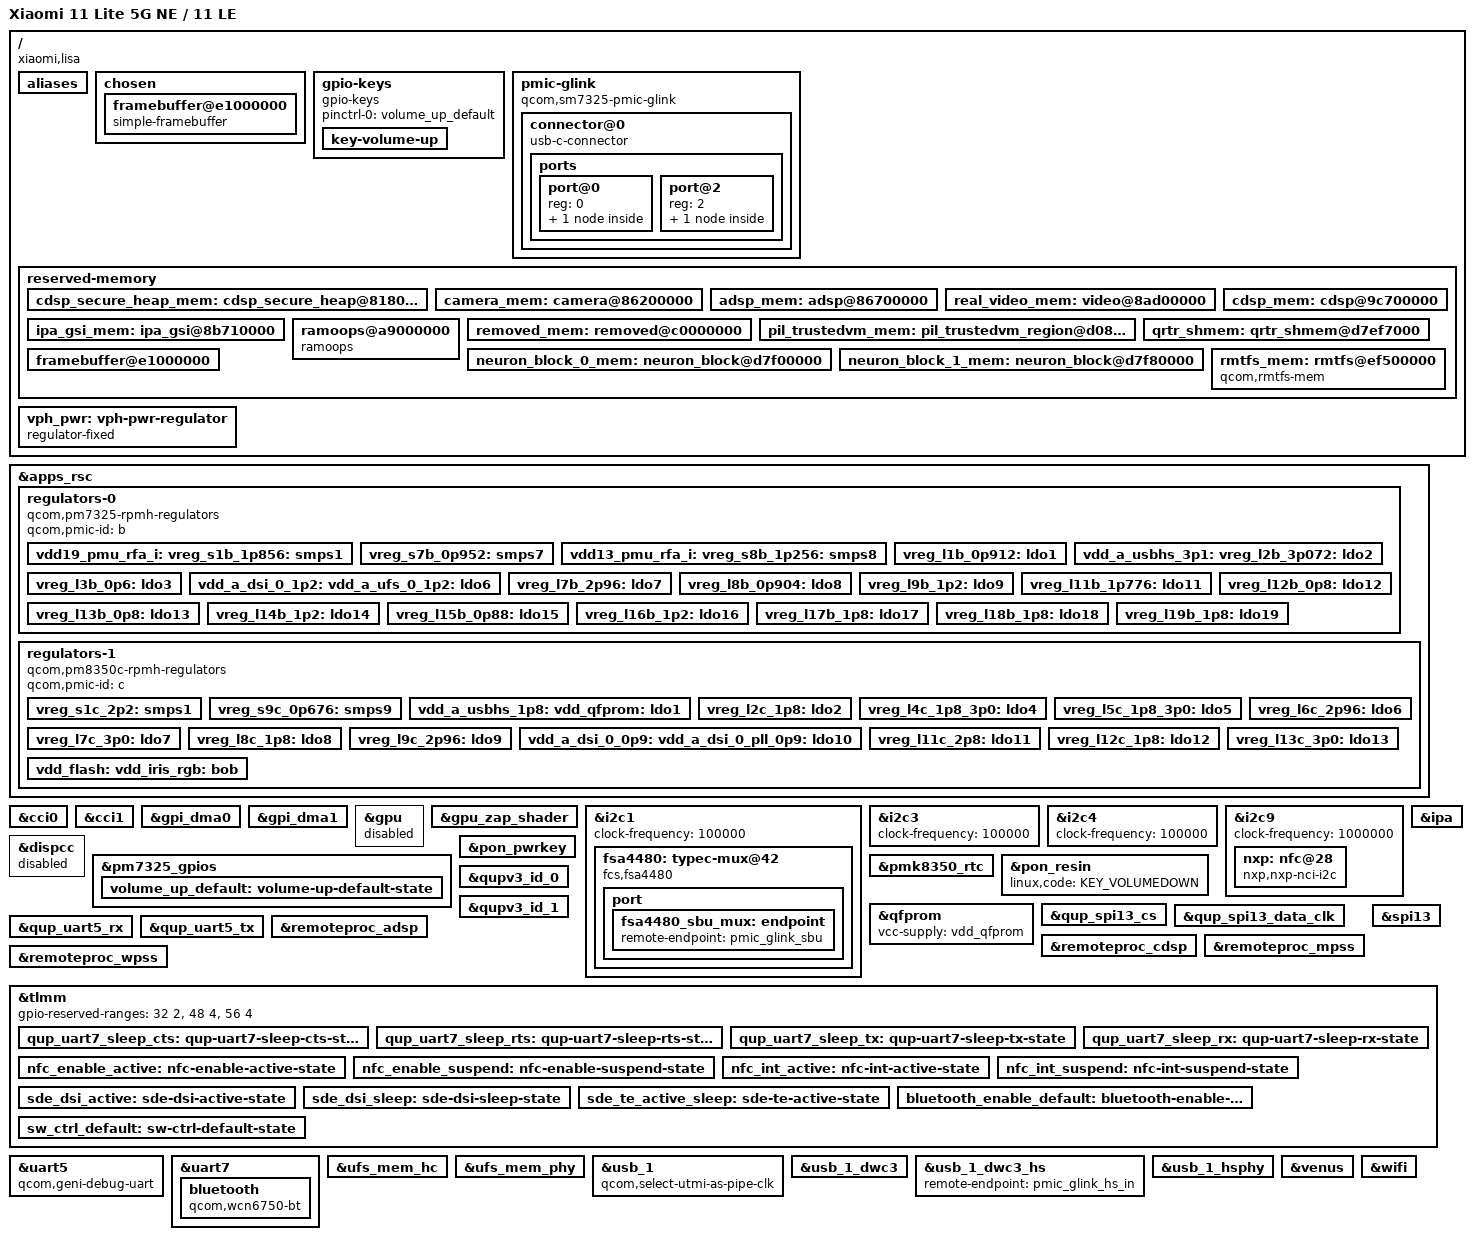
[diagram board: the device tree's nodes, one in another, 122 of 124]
// SPDX-License-Identifier: BSD-3-Clause
/*
 * Copyright (c) 2024, Jens Reidel <adrian@travitia.xyz>
 */

/dts-v1/;

#include <dt-bindings/arm/qcom,ids.h>
#include <dt-bindings/gpio/gpio.h>
#include <dt-bindings/regulator/qcom,rpmh-regulator.h>
#include <dt-bindings/leds/common.h>

#include <dt-bindings/pinctrl/qcom,pmic-gpio.h>
#include "sm7325.dtsi"
#include "pm7325.dtsi"
#include "pm8350b.dtsi" /* PM7325B */
#include "pm8350c.dtsi" /* PM7350C */
#include "pmk8350.dtsi" /* PMK7325 */

/* The following reserved memory regions have different addresses or sizes */
/delete-node/ &adsp_mem;
/delete-node/ &cdsp_mem;
/delete-node/ &rmtfs_mem;

/ {
	model = "Xiaomi 11 Lite 5G NE / 11 LE";
	compatible = "xiaomi,lisa", "qcom,sm7325";
	qcom,msm-id = <QCOM_ID_SM7325 0x10000>;
	qcom,board-id = <0x1000b 0x00>;
	chassis-type = "handset";

	aliases {
		serial0 = &uart5;
		serial1 = &uart7;
	};

	chosen {
		#address-cells = <2>;
		#size-cells = <2>;
		ranges;

		stdout-path = "serial0:115200n8";
		bootargs = "earlycon clk_ignore_unused pd_ignore_unused console=tty0 PMOS_NOSPLASH";

		framebuffer@e1000000 {
			compatible = "simple-framebuffer";
			reg = <0x0 0xe1000000 0x0 (1080 * 2400 * 4)>;
			width = <1080>;
			height = <2400>;
			stride = <(1080 * 4)>;
			format = "a8r8g8b8";
		};
	};

	gpio-keys {
		compatible = "gpio-keys";

		pinctrl-0 = <&volume_up_default>;
		pinctrl-names = "default";

		key-volume-up {
			label = "Volume up";
			gpios = <&pm7325_gpios 6 GPIO_ACTIVE_LOW>;
			linux,code = <KEY_VOLUMEUP>;
		};
	};

	pmic-glink {
		compatible = "qcom,sm7325-pmic-glink",
			     "qcom,pmic-glink";

		#address-cells = <1>;
		#size-cells = <0>;

		connector@0 {
			compatible = "usb-c-connector";
			reg = <0>;
			power-role = "dual";
			data-role = "dual";

			ports {
				#address-cells = <1>;
				#size-cells = <0>;

				port@0 {
					reg = <0>;

					pmic_glink_hs_in: endpoint {
						remote-endpoint = <&usb_1_dwc3_hs>;
					};
				};

				port@2 {
					reg = <2>;

					pmic_glink_sbu: endpoint {
						remote-endpoint = <&fsa4480_sbu_mux>;
					};
				};
			};
		};
	};

	reserved-memory {
		#address-cells = <2>;
		#size-cells = <2>;
		ranges;

		cdsp_secure_heap_mem: cdsp_secure_heap@81800000 {
			reg = <0x0 0x81800000 0x0 0x1e00000>;
			no-map;
		};

		camera_mem: camera@86200000 {
			reg = <0x0 0x86200000 0x0 0x500000>;
			no-map;
		};

		adsp_mem: adsp@86700000 {
			reg = <0x0 0x86700000 0x0 0x4000000>;
			no-map;
		};

		/* Mainline video_mem is downstream cvp_mem */
		real_video_mem: video@8ad00000 {
			reg = <0x0 0x8ad00000 0x0 0x500000>;
			no-map;
		};

		ipa_gsi_mem: ipa_gsi@8b710000 {
			reg = <0x0 0x8b710000 0x0 0xa000>;
			no-map;
		};

		cdsp_mem: cdsp@9c700000 {
			reg = <0x0 0x9c700000 0x0 0x1e00000>;
			no-map;
		};

		ramoops@a9000000 {
			compatible = "ramoops";
			reg = <0x0 0xa9000000 0x0 0x200000>;
			pmsg-size = <0x200000>;
			mem-type = <0x02>;
		};

		removed_mem: removed@c0000000 {
			reg = <0x0 0xc0000000 0x0 0x5100000>;
			no-map;
		};

		pil_trustedvm_mem: pil_trustedvm_region@d0800000 {
			reg = <0x0 0xd0800000 0x0 0x76f7000>;
			no-map;
		};

		qrtr_shmem: qrtr_shmem@d7ef7000 {
			reg = <0x0 0xd7ef7000 0x0 0x9000>;
			no-map;
		};

		neuron_block_0_mem: neuron_block@d7f00000 {
			reg = <0x0 0xd7f00000 0x0 0x80000>;
			no-map;
		};

		neuron_block_1_mem: neuron_block@d7f80000 {
			reg = <0x0 0xd7f80000 0x0 0x80000>;
			no-map;
		};

		framebuffer@e1000000 {
			reg = <0x0 0xe1000000 0x0 (1080 * 2400 * 4)>;
			no-map;
		};

		rmtfs_mem: rmtfs@ef500000 {
			compatible = "qcom,rmtfs-mem";
			reg = <0x0 0xef500000 0x0 0x280000>;
			no-map;

			qcom,client-id = <1>;
			qcom,vmid = <QCOM_SCM_VMID_MSS_MSA>,
				    <QCOM_SCM_VMID_NAV>;
		};
	};

	/*
	thermal-zones {
		camera-thermal {
			polling-delay-passive = <0>;
			polling-delay = <0>;
			thermal-sensors = <&pmk8350_adc_tm 2>;

			trips {
				active-config0 {
					temperature = <125000>;
					hysteresis = <1000>;
					type = "passive";
				};
			};
		};

		chg-skin-thermal {
			polling-delay-passive = <0>;
			polling-delay = <0>;
			thermal-sensors = <&pmk8350_adc_tm 6>;

			trips {
				active-config0 {
					temperature = <125000>;
					hysteresis = <1000>;
					type = "passive";
				};
			};
		};

		conn-thermal {
			polling-delay-passive = <0>;
			polling-delay = <0>;
			thermal-sensors = <&pmk8350_adc_tm 5>;

			trips {
				active-config0 {
					temperature = <125000>;
					hysteresis = <1000>;
					type = "passive";
				};
			};
		};

		quiet-thermal {
			polling-delay-passive = <0>;
			polling-delay = <0>;
			thermal-sensors = <&pmk8350_adc_tm 1>;

			trips {
				active-config0 {
					temperature = <125000>;
					hysteresis = <1000>;
					type = "passive";
				};
			};
		};

		rear-cam-thermal {
			polling-delay-passive = <0>;
			polling-delay = <0>;
			thermal-sensors = <&pmk8350_adc_tm 4>;

			trips {
				active-config0 {
					temperature = <125000>;
					hysteresis = <1000>;
					type = "passive";
				};
			};
		};

		sdm-skin-thermal {
			polling-delay-passive = <0>;
			polling-delay = <0>;
			thermal-sensors = <&pmk8350_adc_tm 3>;

			trips {
				active-config0 {
					temperature = <125000>;
					hysteresis = <1000>;
					type = "passive";
				};
			};
		};

		xo-thermal {
			polling-delay-passive = <0>;
			polling-delay = <0>;
			thermal-sensors = <&pmk8350_adc_tm 0>;

			trips {
				active-config0 {
					temperature = <125000>;
					hysteresis = <1000>;
					type = "passive";
				};
			};
		};
	};
	*/

	vph_pwr: vph-pwr-regulator {
		compatible = "regulator-fixed";
		regulator-name = "vph_pwr";
		regulator-min-microvolt = <3700000>;
		regulator-max-microvolt = <3700000>;
	};

	// S2B is really ebi.lvl but it's there for supply map completeness sake.
	/*
	vreg_s2b_0p7: smpa3-regulator {
		compatible = "regulator-fixed";
		regulator-name = "vreg_s2b_0p7";

		regulator-min-microvolt = <65535>;
		regulator-max-microvolt = <65535>;
		regulator-always-on;
		vin-supply = <&vph_pwr>;
	};
	*/
};

&apps_rsc {
	regulators-0 {
		compatible = "qcom,pm7325-rpmh-regulators";
		qcom,pmic-id = "b";

		/*
		vdd-s1-supply = <&vph_pwr>;
		vdd-s2-supply = <&vph_pwr>;
		vdd-s7-supply = <&vph_pwr>;
		vdd-s8-supply = <&vph_pwr>;

		vdd-l1-l4-l12-l15-supply = <&vreg_s7b_0p952>;
		vdd-l2-l7-supply = <&vreg_bob>;
		vdd-l3-supply = <&vreg_s2b_0p7>;
		vdd-l5-supply = <&vreg_s2b_0p7>;
		vdd-l6-l9-l10-supply = <&vreg_s8b_1p256>;
		vdd-l8-supply = <&vreg_s7b_0p952>;
		vdd-l11-l17-l18-l19-supply = <&vreg_s1b_1p856>;
		vdd-l13-supply = <&vreg_s7b_0p952>;
		vdd-l14-l16-supply = <&vreg_s8b_1p256>;
		*/

		/*
		 * S2, L4-L5 are ARCs:
		 * S2 - ebi.lvl,
		 * L4 - lmx.lvl,
		 * l5 - lcx.lvl.
		 *
		 * L10 are unused.
		 */

		vdd19_pmu_rfa_i:
		vreg_s1b_1p856: smps1 {
			regulator-min-microvolt = <1840000>;
			regulator-max-microvolt = <2040000>;
		};

		vreg_s7b_0p952: smps7 {
			regulator-min-microvolt = <535000>;
			regulator-max-microvolt = <1120000>;
		};

		vdd13_pmu_rfa_i:
		vreg_s8b_1p256: smps8 {
			regulator-min-microvolt = <1200000>;
			regulator-max-microvolt = <1500000>;
			regulator-initial-mode = <RPMH_REGULATOR_MODE_RET>;
		};

		vreg_l1b_0p912: ldo1 {
			regulator-min-microvolt = <825000>;
			regulator-max-microvolt = <925000>;
			regulator-initial-mode = <RPMH_REGULATOR_MODE_HPM>;
		};

		vdd_a_usbhs_3p1:
		vreg_l2b_3p072: ldo2 {
			regulator-min-microvolt = <2700000>;
			regulator-max-microvolt = <3544000>;
			regulator-initial-mode = <RPMH_REGULATOR_MODE_HPM>;
		};

		vreg_l3b_0p6: ldo3 {
			regulator-min-microvolt = <312000>;
			regulator-max-microvolt = <910000>;
			regulator-initial-mode = <RPMH_REGULATOR_MODE_HPM>;
		};

		vdd_a_dsi_0_1p2:
		vdd_a_ufs_0_1p2:
		vreg_l6b_1p2: ldo6 {
			regulator-min-microvolt = <1140000>;
			regulator-max-microvolt = <1260000>;
			regulator-initial-mode = <RPMH_REGULATOR_MODE_HPM>;
			regulator-allow-set-load;
			regulator-allowed-modes = <RPMH_REGULATOR_MODE_LPM
						   RPMH_REGULATOR_MODE_HPM>;
		};

		vreg_l7b_2p96: ldo7 {
			regulator-min-microvolt = <2400000>;
			regulator-max-microvolt = <3544000>;
			regulator-initial-mode = <RPMH_REGULATOR_MODE_HPM>;
			regulator-allow-set-load;
			regulator-allowed-modes = <RPMH_REGULATOR_MODE_LPM
						   RPMH_REGULATOR_MODE_HPM>;
		};

		vreg_l8b_0p904: ldo8 {
			regulator-min-microvolt = <870000>;
			regulator-max-microvolt = <970000>;
			regulator-initial-mode = <RPMH_REGULATOR_MODE_HPM>;
		};

		vreg_l9b_1p2: ldo9 {
			regulator-min-microvolt = <1200000>;
			regulator-max-microvolt = <1304000>;
			regulator-initial-mode = <RPMH_REGULATOR_MODE_HPM>;
			regulator-allow-set-load;
			regulator-allowed-modes = <RPMH_REGULATOR_MODE_LPM
						   RPMH_REGULATOR_MODE_HPM>;
		};

		vreg_l11b_1p776: ldo11 {
			regulator-min-microvolt = <1504000>;
			regulator-max-microvolt = <2000000>;
			regulator-initial-mode = <RPMH_REGULATOR_MODE_HPM>;
		};

		vreg_l12b_0p8: ldo12 {
			regulator-min-microvolt = <751000>;
			regulator-max-microvolt = <824000>;
			regulator-initial-mode = <RPMH_REGULATOR_MODE_HPM>;
		};

		vreg_l13b_0p8: ldo13 {
			regulator-min-microvolt = <530000>;
			regulator-max-microvolt = <824000>;
			regulator-initial-mode = <RPMH_REGULATOR_MODE_HPM>;
		};

		vreg_l14b_1p2: ldo14 {
			regulator-min-microvolt = <1080000>;
			regulator-max-microvolt = <1304000>;
			regulator-initial-mode = <RPMH_REGULATOR_MODE_HPM>;
		};

		vreg_l15b_0p88: ldo15 {
			regulator-min-microvolt = <765000>;
			regulator-max-microvolt = <1020000>;
			regulator-initial-mode = <RPMH_REGULATOR_MODE_HPM>;
		};

		vreg_l16b_1p2: ldo16 {
			regulator-min-microvolt = <1100000>;
			regulator-max-microvolt = <1300000>;
			regulator-initial-mode = <RPMH_REGULATOR_MODE_HPM>;
		};

		vreg_l17b_1p8: ldo17 {
			regulator-min-microvolt = <1700000>;
			regulator-max-microvolt = <1900000>;
			regulator-initial-mode = <RPMH_REGULATOR_MODE_HPM>;
		};

		vreg_l18b_1p8: ldo18 {
			regulator-min-microvolt = <1800000>;
			regulator-max-microvolt = <2000000>;
			regulator-initial-mode = <RPMH_REGULATOR_MODE_HPM>;
		};

		vreg_l19b_1p8: ldo19 {
			regulator-min-microvolt = <1800000>;
			regulator-max-microvolt = <2000000>;
			regulator-initial-mode = <RPMH_REGULATOR_MODE_HPM>;
		};
	};

	regulators-1 {
		compatible = "qcom,pm8350c-rpmh-regulators";
		qcom,pmic-id = "c";

		/*
		vdd-s1-supply = <&vph_pwr>;
		vdd-s2-supply = <&vph_pwr>;
		vdd-s5-supply = <&vph_pwr>;
		vdd-s7-supply = <&vph_pwr>;
		vdd-s9-supply = <&vph_pwr>;
		vdd-s10-supply = <&vph_pwr>;

		vdd-l1-l12-supply = <&vreg_s1b_1p856>;
		vdd-l2-l8-supply = <&vreg_s1b_1p856>;
		*/
		/*
		 * Doesn't work :/
		 * vdd-l3-l4-l5-l7-l13-supply = <&vreg_bob>;
		 */
		/*
		vdd-l6-l9-l11-supply = <&vreg_bob>;
		vdd-l10-supply = <&vreg_s7b_0p952>;

		vdd-bob-supply = <&vph_pwr>;
		*/

		/*
		 * S2, S5, S7, S10 are ARCs:
		 * S2 - cx.lvl,
		 * S5 - mss.lvl,
		 * S7 - gfx.lvl,
		 * S10 - mx.lvl.
		 */

		vreg_s1c_2p2: smps1 {
			regulator-min-microvolt = <2190000>;
			regulator-max-microvolt = <2210000>;
		};

		vreg_s9c_0p676: smps9 {
			regulator-min-microvolt = <1010000>;
			regulator-max-microvolt = <1170000>;
		};

		vdd_a_usbhs_1p8:
		vdd_qfprom:
		vreg_l1c_1p8: ldo1 {
			regulator-min-microvolt = <1800000>;
			regulator-max-microvolt = <1980000>;
			regulator-initial-mode = <RPMH_REGULATOR_MODE_HPM>;
		};

		vreg_l2c_1p8: ldo2 {
			regulator-min-microvolt = <1620000>;
			regulator-max-microvolt = <1980000>;
			regulator-initial-mode = <RPMH_REGULATOR_MODE_HPM>;
		};

		/*
		vreg_l3c_3p0: ldo3 {
			regulator-min-microvolt = <3300000>;
			regulator-max-microvolt = <3300000>;
			regulator-initial-mode = <RPMH_REGULATOR_MODE_HPM>;
			// regulator-always-on;
		};
		*/

		vreg_l4c_1p8_3p0: ldo4 {
			regulator-min-microvolt = <1620000>;
			regulator-max-microvolt = <3300000>;
			regulator-initial-mode = <RPMH_REGULATOR_MODE_HPM>;
		};

		vreg_l5c_1p8_3p0: ldo5 {
			regulator-min-microvolt = <1620000>;
			regulator-max-microvolt = <3300000>;
			regulator-initial-mode = <RPMH_REGULATOR_MODE_HPM>;
		};

		vreg_l6c_2p96: ldo6 {
			regulator-min-microvolt = <1650000>;
			regulator-max-microvolt = <3544000>;
			regulator-initial-mode = <RPMH_REGULATOR_MODE_HPM>;
		};

		vreg_l7c_3p0: ldo7 {
			regulator-min-microvolt = <3000000>;
			regulator-max-microvolt = <3544000>;
			regulator-initial-mode = <RPMH_REGULATOR_MODE_HPM>;
		};

		vreg_l8c_1p8: ldo8 {
			regulator-min-microvolt = <1620000>;
			regulator-max-microvolt = <2000000>;
			regulator-initial-mode = <RPMH_REGULATOR_MODE_HPM>;
			regulator-always-on;
		};

		vreg_l9c_2p96: ldo9 {
			regulator-min-microvolt = <2700000>;
			regulator-max-microvolt = <3544000>;
			regulator-initial-mode = <RPMH_REGULATOR_MODE_HPM>;
		};

		vdd_a_dsi_0_0p9:
		vdd_a_dsi_0_pll_0p9:
		vdd_a_ufs_0_core:
		vdd_a_usbhs_core:
		vreg_l10c: ldo10 {
			regulator-min-microvolt = <720000>;
			regulator-max-microvolt = <1050000>;
			regulator-initial-mode = <RPMH_REGULATOR_MODE_HPM>;
			regulator-allow-set-load;
			regulator-allowed-modes = <RPMH_REGULATOR_MODE_LPM
						   RPMH_REGULATOR_MODE_HPM>;
		};

		vreg_l11c_2p8: ldo11 {
			regulator-min-microvolt = <2800000>;
			regulator-max-microvolt = <3544000>;
			regulator-initial-mode = <RPMH_REGULATOR_MODE_HPM>;
		};

		vreg_l12c_1p8: ldo12 {
			regulator-min-microvolt = <1650000>;
			regulator-max-microvolt = <2000000>;
			regulator-initial-mode = <RPMH_REGULATOR_MODE_HPM>;
		};

		vreg_l13c_3p0: ldo13 {
			regulator-min-microvolt = <2700000>;
			regulator-max-microvolt = <3544000>;
			regulator-initial-mode = <RPMH_REGULATOR_MODE_HPM>;
		};

		vdd_flash:
		vdd_iris_rgb:
		vdd_mic_bias:
		vreg_bob: bob {
			regulator-min-microvolt = <3008000>;
			regulator-max-microvolt = <3960000>;
			regulator-initial-mode = <RPMH_REGULATOR_MODE_AUTO>;
		};
	};
};

&cci0 {
	status = "okay";
};

&cci1 {
	status = "okay";
};

&gpi_dma0 {
	status = "okay";
};

&gpi_dma1 {
	status = "okay";
};

&gpu {
	status = "okay";
};

&gpu_zap_shader {
	firmware-name = "qcom/sm7325/xiaomi/lisa/a660_zap.mbn";
};

&i2c1 {
	clock-frequency = <100000>;
	status = "okay";

	/* awinic,aw210xx_led @ 20 */

	fsa4480: typec-mux@42 {
		compatible = "fcs,fsa4480";
		reg = <0x42>;

		interrupts-extended = <&tlmm 2 IRQ_TYPE_LEVEL_LOW>;

		vcc-supply = <&vreg_bob>;
		mode-switch;
		orientation-switch;

		port {
			fsa4480_sbu_mux: endpoint {
				remote-endpoint = <&pmic_glink_sbu>;
			};
		};
	};

	/*
	 * I guess this is also not used:
	 *
	 * nq rtc6226 @ 64
	 */
};

&i2c3 {
	clock-frequency = <100000>;
	status = "okay";

	/* tfa,tfa98xx @ 34 */
	/* tfa,tfa98xx @ 35 */
};

&i2c4 {
	clock-frequency = <100000>;
	status = "okay";

	/* awinic,aw8624_haptic @ 5a */
};

&i2c9 {
	clock-frequency = <1000000>;
	status = "okay";

	nxp: nfc@28 {
		compatible = "nxp,nxp-nci-i2c";
		reg = <0x28>;

		interrupt-parent = <&tlmm>;
		interrupts = <41 IRQ_TYPE_NONE>;

		enable-gpios = <&tlmm 38 GPIO_ACTIVE_HIGH>;
		firmware-gpios = <&tlmm 40 GPIO_ACTIVE_HIGH>;

		pinctrl-names = "default", "sleep";
		pinctrl-0 = <&nfc_enable_active>, <&nfc_int_active>;
		pinctrl-1 = <&nfc_enable_suspend>, <&nfc_int_suspend>;
	};
};

&ipa {
	qcom,gsi-loader = "self";
	memory-region = <&ipa_fw_mem>;
	firmware-name = "qcom/sm7325/xiaomi/lisa/ipa_fws.mbn";
	status = "okay";
};

&dispcc {
	status = "disabled";
};

&gpu {
	status = "disabled";
};

/*
&mdss {
	status = "okay";
};

&mdss_dsi {
	vdda-supply = <&vdd_a_dsi_0_1p2>;
	status = "okay";

	drm_panel: panel@0 {
		compatible = "mdss,k9d-36-02-0a-dsc";
		reg = <0>;

		reset-gpios = <&tlmm 44 GPIO_ACTIVE_LOW>;

		vdd-supply = <&vreg_l13c_3p0>;
		vddio-supply = <&vreg_l12c_1p8>;

		pinctrl-0 = <&sde_dsi_active &sde_te_active_sleep>;
		pinctrl-1 = <&sde_dsi_sleep &sde_te_active_sleep>;
		pinctrl-names = "default", "sleep";

		port {
			panel_in: endpoint {
				remote-endpoint = <&mdss_dsi0_out>;
			};
		};
	};
};

&mdss_dsi0_out {
	data-lanes = <0 1 2 3>;
	remote-endpoint = <&panel_in>;
};

&mdss_dsi_phy {
	vdds-supply = <&vdd_a_dsi_0_0p9>;
	status = "okay";
};
*/

&pm7325_gpios {
	volume_up_default: volume-up-default-state {
		pins = "gpio6";
		function = PMIC_GPIO_FUNC_NORMAL;
		power-source = <1>;
		bias-pull-up;
		input-enable;
	};
};

/*
&pm8350c_flash {
	status = "okay";

	led-0 {
		function = LED_FUNCTION_FLASH;
		color = <LED_COLOR_ID_WHITE>;
		led-sources = <1>, <4>;
		led-max-microamp = <500000>;
		flash-max-microamp = <1500000>;
		flash-max-timeout-us = <1280000>;
	};
};
*/

&pmk8350_rtc {
	status = "okay";
};

&pon_pwrkey {
	status = "okay";
};

&pon_resin {
	linux,code = <KEY_VOLUMEDOWN>;
	status = "okay";
};

&qfprom {
	vcc-supply = <&vdd_qfprom>;
};

&qup_spi13_cs {
	drive-strength = <6>;
	bias-disable;
};

&qup_spi13_data_clk {
	drive-strength = <6>;
	bias-disable;
};

&qup_uart5_rx {
	drive-strength = <2>;
	bias-disable;
};

&qup_uart5_tx {
	drive-strength = <2>;
	bias-disable;
};

&qupv3_id_0 {
	status = "okay";
};

&qupv3_id_1 {
	status = "okay";
};

&remoteproc_adsp {
	firmware-name = "qcom/sm7325/xiaomi/lisa/adsp.mbn";
	status = "okay";
};

&remoteproc_cdsp {
	firmware-name = "qcom/sm7325/xiaomi/lisa/cdsp.mbn";
	status = "okay";
};

&remoteproc_mpss {
	firmware-name = "qcom/sm7325/xiaomi/lisa/modem.mbn";
	status = "okay";
};

&remoteproc_wpss {
	firmware-name = "qcom/sm7325/xiaomi/lisa/wpss.mbn";
	status = "okay";
};

&spi13 {
	status = "okay";

	/* xiaomi,k9-spi @ 0 */
};


&tlmm {
	/*
	 * 32-33: SMB1394 (SPMI)
	 * 56-59: fingerprint reader (SPI)
	 */
	gpio-reserved-ranges = <32 2>, <48 4>, <56 4>;

	qup_uart7_sleep_cts: qup-uart7-sleep-cts-state {
		pins = "gpio28";
		function = "gpio";
		/*
		 * Configure a bias-bus-hold on CTS to lower power
		 * usage when Bluetooth is turned off. Bus hold will
		 * maintain a low power state regardless of whether
		 * the Bluetooth module drives the pin in either
		 * direction or leaves the pin fully unpowered.
		 */
		bias-bus-hold;
	};

	qup_uart7_sleep_rts: qup-uart7-sleep-rts-state {
		pins = "gpio29";
		function = "gpio";
		/*
		 * Configure pull-down on RTS. As RTS is active low
		 * signal, pull it low to indicate the BT SoC that it
		 * can wakeup the system anytime from suspend state by
		 * pulling RX low (by sending wakeup bytes).
		 */
		bias-pull-down;
	};

	qup_uart7_sleep_tx: qup-uart7-sleep-tx-state {
		pins = "gpio30";
		function = "gpio";
		/*
		 * Configure pull-up on TX when it isn't actively driven
		 * to prevent BT SoC from receiving garbage during sleep.
		 */
		bias-pull-up;
	};

	qup_uart7_sleep_rx: qup-uart7-sleep-rx-state {
		pins = "gpio31";
		function = "gpio";
		/*
		 * Configure a pull-up on RX. This is needed to avoid
		 * garbage data when the TX pin of the Bluetooth module
		 * is floating which may cause spurious wakeups.
		 */
		bias-pull-up;
	};

	nfc_enable_active: nfc-enable-active-state {
		pins = "gpio38", "gpio40", "gpio39";
		function = "gpio";
		drive-strength = <2>;
		bias-disable;
	};

	nfc_enable_suspend: nfc-enable-suspend-state {
		pins = "gpio38", "gpio40", "gpio39";
		function = "gpio";
		drive-strength = <2>;
		bias-disable;
	};

	nfc_int_active: nfc-int-active-state {
		pins = "gpio41";
		function = "gpio";
		drive-strength = <2>;
		bias-pull-down;
	};

	nfc_int_suspend: nfc-int-suspend-state {
		pins = "gpio41";
		function = "gpio";
		drive-strength = <2>;
		bias-pull-down;
	};

	sde_dsi_active: sde-dsi-active-state {
		pins = "gpio44";
		function = "gpio";
		drive-strength = <8>;
		bias-disable;
	};

	sde_dsi_sleep: sde-dsi-sleep-state {
		pins = "gpio44";
		function = "gpio";
		drive-strength = <2>;
		bias-pull-down;
	};

	sde_te_active_sleep: sde-te-active-state {
		pins = "gpio80";
		function = "mdp_vsync";
		drive-strength = <2>;
		bias-pull-down;
	};

	bluetooth_enable_default: bluetooth-enable-default-state {
		pins = "gpio85";
		function = "gpio";
		output-low;
		bias-disable;
	};

	sw_ctrl_default: sw-ctrl-default-state {
		pins = "gpio86";
		function = "gpio";
		bias-pull-down;
	};
};

&uart5 {
	compatible = "qcom,geni-debug-uart";
	status = "okay";
};

&uart7 {
	/delete-property/interrupts;
	interrupts-extended = <&intc GIC_SPI 608 IRQ_TYPE_LEVEL_HIGH>,
			      <&tlmm 31 IRQ_TYPE_EDGE_FALLING>;

	pinctrl-1 = <&qup_uart7_sleep_cts>,
		    <&qup_uart7_sleep_rts>,
		    <&qup_uart7_sleep_tx>,
		    <&qup_uart7_sleep_rx>;
	pinctrl-names = "default", "sleep";

	status = "okay";

	bluetooth: bluetooth {
		compatible = "qcom,wcn6750-bt";

		pinctrl-0 = <&bluetooth_enable_default>, <&sw_ctrl_default>;
		pinctrl-names = "default";

		enable-gpios = <&tlmm 85 GPIO_ACTIVE_HIGH>;
		swctrl-gpios = <&tlmm 86 GPIO_ACTIVE_HIGH>;

		vddio-supply = <&vreg_l19b_1p8>;
		vddaon-supply = <&vreg_s7b_0p952>;
		vddbtcxmx-supply = <&vreg_s7b_0p952>;
		vddrfacmn-supply = <&vreg_s7b_0p952>;
		vddrfa0p8-supply = <&vreg_s7b_0p952>;
		vddrfa1p2-supply = <&vdd13_pmu_rfa_i>;
		vddrfa1p7-supply = <&vdd19_pmu_rfa_i>;
		vddrfa2p2-supply = <&vreg_s1c_2p2>;
		vddasd-supply = <&vreg_l11c_2p8>;
		max-speed = <3200000>;

		qcom,local-bd-address-broken;
	};
};

&ufs_mem_hc {
	reset-gpios = <&tlmm 175 GPIO_ACTIVE_LOW>;

	vcc-supply = <&vreg_l7b_2p96>;
	vcc-max-microamp = <800000>;
	/*
	 * Technically l9b enables an eLDO (supplied by s1b) which then powers
	 * VCCQ2 of the UFS.
	 */
	vccq-supply = <&vreg_l9b_1p2>;
	vccq-max-microamp = <900000>;

	status = "okay";
};

&ufs_mem_phy {
	vdda-phy-supply = <&vdd_a_ufs_0_core>;
	vdda-pll-supply = <&vdd_a_ufs_0_1p2>;
	status = "okay";
};

&usb_1 {
	/* USB 2.0 only */
	qcom,select-utmi-as-pipe-clk;
	status = "okay";
};

&usb_1_dwc3 {
	dr_mode = "otg";
	usb-role-switch;
	maximum-speed = "high-speed";
	/* Remove USB3 phy */
	phys = <&usb_1_hsphy>;
	phy-names = "usb2-phy";
};

&usb_1_dwc3_hs {
	remote-endpoint = <&pmic_glink_hs_in>;
};

&usb_1_hsphy {
	vdda-pll-supply = <&vdd_a_usbhs_core>;
	vdda18-supply = <&vdd_a_usbhs_1p8>;
	vdda33-supply = <&vdd_a_usbhs_3p1>;
	status = "okay";
};

&venus {
	firmware-name = "qcom/sm7325/xiaomi/lisa/vpu20_1v.mbn";
	status = "okay";
};

&wifi {
	status = "okay";
};
